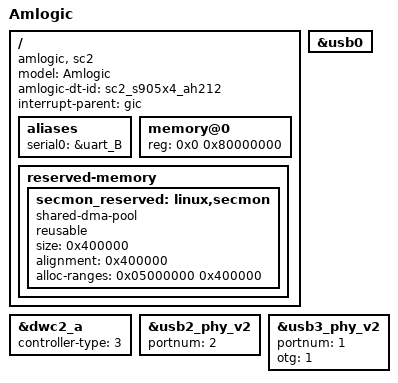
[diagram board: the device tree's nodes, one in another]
// SPDX-License-Identifier: (GPL-2.0+ OR MIT)
/*
 * Copyright (c) 2019 Amlogic, Inc. All rights reserved.
 */

/dts-v1/;

#include "meson-sc2.dtsi"
#include "partition_mbox.dtsi"
#include <dt-bindings/input/input.h>

/ {
	model = "Amlogic";
	amlogic-dt-id = "sc2_s905x4_ah212";
	compatible = "amlogic, sc2";
	interrupt-parent = <&gic>;
	#address-cells = <1>;
	#size-cells = <1>;

	aliases {
		serial0 = &uart_B;
	};

	memory@0 {
		device_type = "memory";
		reg = <0x0 0x80000000>;
	};

	reserved-memory {
		secmon_reserved:linux,secmon {
			compatible = "shared-dma-pool";
			reusable;
			size = <0x400000>;
			alignment = <0x400000>;
			alloc-ranges = <0x05000000 0x400000>;
		};
	};
};

&dwc2_a {
	status = "okay";
	/** 0: normal, 1: otg+dwc3 host only, 2: otg+dwc3 device only*/
	controller-type = <3>;
};

&usb0 {
	status = "okay";
};

&usb2_phy_v2 {
	status = "okay";
	portnum = <2>;
};

&usb3_phy_v2 {
	status = "okay";
	portnum = <1>;
	otg = <1>;
	/*gpio-vbus-power = "GPIOH_6";*/
	/*gpios = <&gpio GPIOH_6 GPIO_ACTIVE_HIGH>;*/
};
